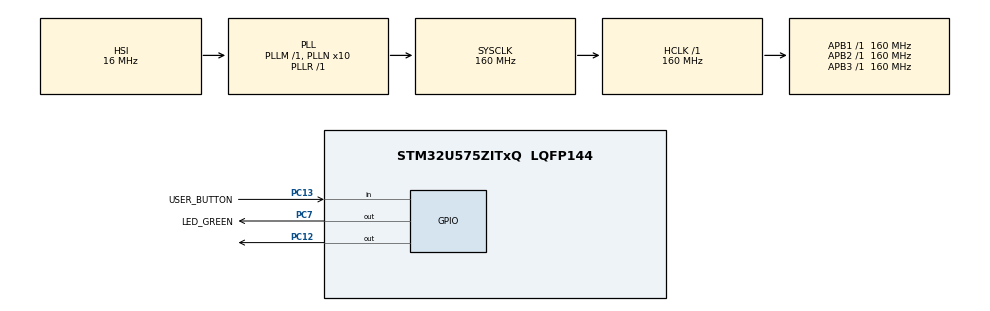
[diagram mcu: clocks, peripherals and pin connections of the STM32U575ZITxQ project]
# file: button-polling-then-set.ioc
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CORTEX_M33_NS.userName=CORTEX_M33
Mcu.Family=STM32U5
Mcu.Name=STM32U575ZITxQ
Mcu.Package=LQFP144
NVIC.PriorityGroup=NVIC_PRIORITYGROUP_3
PA13\ (JTMS/SWDIO).Mode=Trace_Asynchronous_SW
PA13\ (JTMS/SWDIO).Signal=DEBUG_JTMS-SWDIO
PA14\ (JTCK/SWCLK).Mode=Trace_Asynchronous_SW
PA14\ (JTCK/SWCLK).Signal=DEBUG_JTCK-SWCLK
PB3\ (JTDO/TRACESWO).Mode=Trace_Asynchronous_SW
PB3\ (JTDO/TRACESWO).Signal=DEBUG_JTDO-SWO
PC12.Signal=GPIO_Output
PC13.GPIO_Label=USER_BUTTON
PC13.Signal=GPIO_Input
PC7.GPIO_Label=LED_GREEN
PC7.Signal=GPIO_Output
ProjectManager.HeapSize=0x200
ProjectManager.StackSize=0x400
ProjectManager.TargetToolchain=STM32CubeIDE
RCC.ADCFreq_Value=16000000
RCC.AHBFreq_Value=160000000
RCC.APB1Freq_Value=160000000
RCC.APB1TimFreq_Value=160000000
RCC.APB2Freq_Value=160000000
RCC.APB2TimFreq_Value=160000000
RCC.APB3Freq_Value=160000000
RCC.CortexFreq_Value=160000000
RCC.DACCLockSelectionVirtual=RCC_DAC1CLKSOURCE_LSI
RCC.EPOD_VALUE=16000000
RCC.HCLKFreq_Value=160000000
RCC.HSE_VALUE=16000000
RCC.HSI48_VALUE=48000000
RCC.HSI_VALUE=16000000
RCC.LSE_VALUE=32768
RCC.LSIDIV_VALUE=32000
RCC.MSIClockRange=RCC_MSIRANGE_0
RCC.MSI_VALUE=48000000
RCC.PLL1R=1
RCC.PLLFRACN=0
RCC.PLLN=10
RCC.PLLSourceVirtual=RCC_PLLSOURCE_HSI
RCC.SYSCLKFreq_VALUE=160000000
RCC.SYSCLKSource=RCC_SYSCLKSOURCE_PLLCLK
RCC.USBFreq_Value=48000000
RCC.VCOOutputFreq_Value=160000000
VP_ICACHE_VS_ICACHE.Mode=DefaultMode
VP_LPBAMQUEUE_VS_QUEUE.Mode=QUEUEMODE
VP_LPBAM_VS_SIG1.Mode=SmartRun
VP_LPBAM_VS_SIG4.Mode=LPDMA1
VP_MEMORYMAP_VS_MEMORYMAP.Mode=CurAppReg
VP_PWR_VS_SECSignals.Mode=Security/Privilege
board=NUCLEO-U575ZI-Q

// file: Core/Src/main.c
/* USER CODE BEGIN Header */
/**
 ******************************************************************************
 * @file           : main.c
 * @brief          : Main program body
 ******************************************************************************
 * @attention
 *
 * Copyright (c) 2024 STMicroelectronics.
 * All rights reserved.
 *
 * This software is licensed under terms that can be found in the LICENSE file
 * in the root directory of this software component.
 * If no LICENSE file comes with this software, it is provided AS-IS.
 *
 ******************************************************************************
 */
/* USER CODE END Header */
#include "main.h"

/* USER CODE BEGIN PV */
uint32_t begin;
uint32_t end;
uint32_t diff;
/* USER CODE END PV */

void SystemClock_Config(void);
static void MX_GPIO_Init(void);
static void MX_ICACHE_Init(void);

/* USER CODE BEGIN 0 */
int _write(int le, char *ptr, int len) {
	int DataIdx;

	for (DataIdx = 0; DataIdx < len; DataIdx++) {
		ITM_SendChar(*ptr++);
	}

	return len;
}
/* USER CODE END 0 */

int main(void)
{

  /* USER CODE BEGIN 1 */
	begin = DWT->CYCCNT;
  /* USER CODE END 1 */

  /* MCU Configuration--------------------------------------------------------*/

  /* Reset of all peripherals, Initializes the Flash interface and the Systick. */
  HAL_Init();

  /* Configure the system clock */
  SystemClock_Config();

  /* Initialize all configured peripherals */
  MX_GPIO_Init();
  MX_ICACHE_Init();
  /* USER CODE BEGIN 2 */
	end = DWT->CYCCNT;
	diff = end - begin;
	printf("%u\n", diff);
  /* USER CODE END 2 */

  /* Infinite loop */
  /* USER CODE BEGIN WHILE */
	while (1) {
		if (HAL_GPIO_ReadPin(USER_BUTTON_GPIO_Port, USER_BUTTON_Pin)) {
			HAL_GPIO_WritePin(GPIOC, GPIO_PIN_12, 1);
		} else {
			HAL_GPIO_WritePin(GPIOC, GPIO_PIN_12, 0);
		}
    /* USER CODE END WHILE */

	}
}

void SystemClock_Config(void)
{
  RCC_OscInitTypeDef RCC_OscInitStruct = {0};
  RCC_ClkInitTypeDef RCC_ClkInitStruct = {0};

  /** Configure the main internal regulator output voltage
  */
  if (HAL_PWREx_ControlVoltageScaling(PWR_REGULATOR_VOLTAGE_SCALE1) != HAL_OK)
  {
    Error_Handler();
  }

  /** Initializes the CPU, AHB and APB buses clocks
  */
  RCC_OscInitStruct.OscillatorType = RCC_OSCILLATORTYPE_HSI;
  RCC_OscInitStruct.HSIState = RCC_HSI_ON;
  RCC_OscInitStruct.HSICalibrationValue = RCC_HSICALIBRATION_DEFAULT;
  RCC_OscInitStruct.PLL.PLLState = RCC_PLL_ON;
  RCC_OscInitStruct.PLL.PLLSource = RCC_PLLSOURCE_HSI;
  RCC_OscInitStruct.PLL.PLLMBOOST = RCC_PLLMBOOST_DIV1;
  RCC_OscInitStruct.PLL.PLLM = 1;
  RCC_OscInitStruct.PLL.PLLN = 10;
  RCC_OscInitStruct.PLL.PLLP = 2;
  RCC_OscInitStruct.PLL.PLLQ = 2;
  RCC_OscInitStruct.PLL.PLLR = 1;
  RCC_OscInitStruct.PLL.PLLRGE = RCC_PLLVCIRANGE_1;
  RCC_OscInitStruct.PLL.PLLFRACN = 0;
  if (HAL_RCC_OscConfig(&RCC_OscInitStruct) != HAL_OK)
  {
    Error_Handler();
  }

  /** Initializes the CPU, AHB and APB buses clocks
  */
  RCC_ClkInitStruct.ClockType = RCC_CLOCKTYPE_HCLK|RCC_CLOCKTYPE_SYSCLK
                              |RCC_CLOCKTYPE_PCLK1|RCC_CLOCKTYPE_PCLK2
                              |RCC_CLOCKTYPE_PCLK3;
  RCC_ClkInitStruct.SYSCLKSource = RCC_SYSCLKSOURCE_PLLCLK;
  RCC_ClkInitStruct.AHBCLKDivider = RCC_SYSCLK_DIV1;
  RCC_ClkInitStruct.APB1CLKDivider = RCC_HCLK_DIV1;
  RCC_ClkInitStruct.APB2CLKDivider = RCC_HCLK_DIV1;
  RCC_ClkInitStruct.APB3CLKDivider = RCC_HCLK_DIV1;

  if (HAL_RCC_ClockConfig(&RCC_ClkInitStruct, FLASH_LATENCY_4) != HAL_OK)
  {
    Error_Handler();
  }
}

static void MX_ICACHE_Init(void)
{

  /** Enable instruction cache (default 2-ways set associative cache)
  */
  if (HAL_ICACHE_Enable() != HAL_OK)
  {
    Error_Handler();
  }

}

static void MX_GPIO_Init(void)
{
  GPIO_InitTypeDef GPIO_InitStruct = {0};

  /* GPIO Ports Clock Enable */
  __HAL_RCC_GPIOC_CLK_ENABLE();
  __HAL_RCC_GPIOA_CLK_ENABLE();
  __HAL_RCC_GPIOB_CLK_ENABLE();

  /*Configure GPIO pin Output Level */
  HAL_GPIO_WritePin(GPIOC, LED_GREEN_Pin|GPIO_PIN_12, GPIO_PIN_RESET);

  /*Configure GPIO pin : USER_BUTTON_Pin */
  GPIO_InitStruct.Pin = USER_BUTTON_Pin;
  GPIO_InitStruct.Mode = GPIO_MODE_INPUT;
  GPIO_InitStruct.Pull = GPIO_NOPULL;
  HAL_GPIO_Init(USER_BUTTON_GPIO_Port, &GPIO_InitStruct);

  /*Configure GPIO pins : LED_GREEN_Pin PC12 */
  GPIO_InitStruct.Pin = LED_GREEN_Pin|GPIO_PIN_12;
  GPIO_InitStruct.Mode = GPIO_MODE_OUTPUT_PP;
  GPIO_InitStruct.Pull = GPIO_NOPULL;
  GPIO_InitStruct.Speed = GPIO_SPEED_FREQ_LOW;
  HAL_GPIO_Init(GPIOC, &GPIO_InitStruct);

}

void Error_Handler(void)
{
	__disable_irq();
	while (1) {
	}
}
